# apollo510 register map
Vendor: Ambiq Micro; Series: Apollo; File version: 1.0
CPU: CM55 r1p1, little endian, MPU, FPU, double-precision FPU, DSP, I-cache, D-cache, VTOR, ITCM, DTCM, 4 interrupt priority bits, 0 interrupts, 8 SAU regions
Registers are 32-bit, read-write, reset 0x0 unless marked. A register's access mark holds for its fields unless they carry their own. Offsets are from the block's base; [hi:lo] are bit positions; 'fields as' and 'values as' point back to an identical list.

## PDM0 — PDM Audio
Base 0x40201000
Same registers: PDM1 0x40202000, PDM2 0x40203000, PDM3 0x40204000
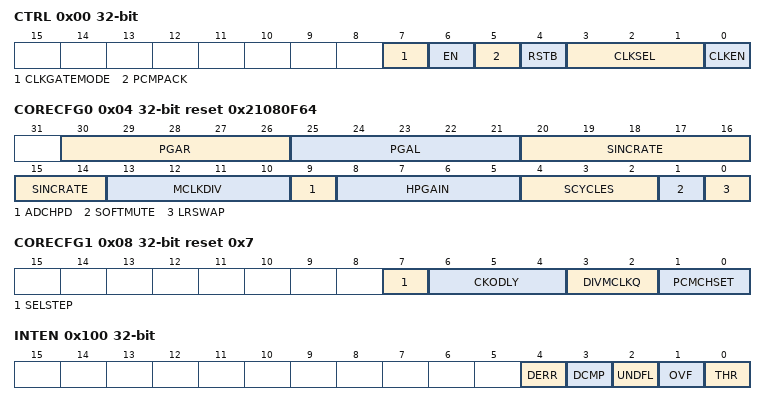
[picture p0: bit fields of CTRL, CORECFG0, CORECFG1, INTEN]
0x00 CTRL — PDM Control
  [7] CLKGATEMODE — Clock gating mode. 0 = clock always enabled when DMA is enabled. 1 = clock is enabled when there is actual DMA transfer
  [6] EN — PDM enable register
    0=DIS (Disable PDM.); 1=EN (Enable PDM.)
  [5] PCMPACK — Enable PCM packing. Only 24-bit unpacked mode supported.
    0=DIS (Disable PCM packing.); 1=EN (Enable PCM packing.)
  [4] RSTB — Reset IP core. 0 puts the core in reset; 1 takes the core out of reset.
    0=RESET (Put the core in reset.); 1=NORMAL (Core not in reset.)
  [3:1] CLKSEL — PDM Master Clock select (24.576MHz).
    0=HFRC2_31MHz (31MHz sourced from the HFRC2); 1=XTAL_HS (High Frequency XTAL); 2=HFRC_24MHz (24MHz sourced from the HFRC); 3=XTAL_HS_DIV2 (High Frequency XTAL Divide by 2); 4=XTAL_HS_DIV4 (High Frequency XTAL Divide by 4); 5=EXTREFCLK (External reference clock); 6=OFF (Static 0)
  [0] CLKEN — PDM Clock enable. If multiple clocks are enabled, priority is HFRC2, HF XTAL, HFRC.
    0=DIS (Disable serial clock); 1=EN (Enable serial clock)
0x04 CORECFG0 reset 0x21080F64 — PDM to PCM Core Configuration
  [30:26] PGAR — Right Channel PGA Gain: +1.5dB/step, -12dB ~ +34.5dB;
    0=M12_0DB (Right channel PGA gain = -12.0 dB); 1=M10_5DB (Right channel PGA gain = -10.5 dB); 2=M9_0DB (Right channel PGA gain = -9.0 dB); 3=M7_5DB (Right channel PGA gain = -7.5 dB); 4=M6_0DB (Right channel PGA gain = -6.0 dB); 5=M4_5DB (Right channel PGA gain = -4.5 dB); 6=M3_0DB (Right channel PGA gain = -3.0 dB); 7=M1_5DB (Right channel PGA gain = -1.5 dB); 8=0DB (Right channel PGA gain = 0 DB); 9=P1_5DB (Right channel PGA gain = 1.5 dB); 10=P3_0DB (Right channel PGA gain = 3.0 dB); 11=P4_5DB (Right channel PGA gain = 4.5 dB); 12=P6_0DB (Right channel PGA gain = 6.0 DB); 13=P7_5DB (Right channel PGA gain = 7.5 dB); 14=P9_0DB (Right channel PGA gain = 9.0 dB); 15=P10_5DB (Right channel PGA gain = 10.5 dB); 16=P12_0DB (Right channel PGA gain = 12.0 DB); 17=P13_5DB (Right channel PGA gain = 13.5 dB); 18=P15_0DB (Right channel PGA gain = 15.0 dB); 19=P16_5DB (Right channel PGA gain = 16.5 dB); 20=P18_0DB (Right channel PGA gain = 18.0 DB); 21=P19_5DB (Right channel PGA gain = 19.5 dB); 22=P21_0DB (Right channel PGA gain = 21.0 dB); 23=P22_5DB (Right channel PGA gain = 22.5 dB); 24=P24_0DB (Right channel PGA gain = 24.0 DB); 25=P25_5DB (Right channel PGA gain = 25.5 dB); 26=P27_0DB (Right channel PGA gain = 27.0 dB); 27=P28_5DB (Right channel PGA gain = 28.5 dB); 28=P30_0DB (Right channel PGA gain = 30.0 DB); 29=P31_5DB (Right channel PGA gain = 31.5 dB); 30=P33_0DB (Right channel PGA gain = 33.0 dB); 31=P34_5DB (Right channel PGA gain = 34.5 dB)
  [25:21] PGAL — Left Channel PGA Gain: +1.5dB/step, -12dB ~ +34.5dB; enum name = M12_0DB value = 0x0 desc = Left channel PGA gain = -12.0 dB
    1=M10_5DB (Left channel PGA gain = -10.5 dB); 2=M9_0DB (Left channel PGA gain = -9.0 dB); 3=M7_5DB (Left channel PGA gain = -7.5 dB); 4=M6_0DB (Left channel PGA gain = -6.0 dB); 5=M4_5DB (Left channel PGA gain = -4.5 dB); 6=M3_0DB (Left channel PGA gain = -3.0 dB); 7=M1_5DB (Left channel PGA gain = -1.5 dB); 8=0DB (Left channel PGA gain = 0 DB); 9=P1_5DB (Left channel PGA gain = 1.5 dB); 10=P3_0DB (Left channel PGA gain = 3.0 dB); 11=P4_5DB (Left channel PGA gain = 4.5 dB); 12=P6_0DB (Left channel PGA gain = 6.0 DB); 13=P7_5DB (Left channel PGA gain = 7.5 dB); 14=P9_0DB (Left channel PGA gain = 9.0 dB); 15=P10_5DB (Left channel PGA gain = 10.5 dB); 16=P12_0DB (Left channel PGA gain = 12.0 DB); 17=P13_5DB (Left channel PGA gain = 13.5 dB); 18=P15_0DB (Left channel PGA gain = 15.0 dB); 19=P16_5DB (Left channel PGA gain = 16.5 dB); 20=P18_0DB (Left channel PGA gain = 18.0 DB); 21=P19_5DB (Left channel PGA gain = 19.5 dB); 22=P21_0DB (Left channel PGA gain = 21.0 dB); 23=P22_5DB (Left channel PGA gain = 22.5 dB); 24=P24_0DB (Left channel PGA gain = 24.0 DB); 25=P25_5DB (Left channel PGA gain = 25.5 dB); 26=P27_0DB (Left channel PGA gain = 27.0 dB); 27=P28_5DB (Left channel PGA gain = 28.5 dB); 28=P30_0DB (Left channel PGA gain = 30.0 DB); 29=P31_5DB (Left channel PGA gain = 31.5 dB); 30=P33_0DB (Left channel PGA gain = 33.0 dB); 31=P34_5DB (Left channel PGA gain = 34.5 dB)
  [20:14] SINCRATE — Sinc decimation rate. SINC_RATE = OSR /2. OSR = Fsin / Fsout. Must be even. 16 to 64 allowed. 96 allowed for special configuration.
  [13:10] MCLKDIV — PDMA_CKO frequency divisor. MCLKDIV > 0. MCLKDIV = 0 PROHIBITED. MCLKDIV = (PDM_CLK /Fsin / (DIVMCLKQ + 1)) -1
  [9] ADCHPD — Disable high pass filter when = 1
    0=DIS (Disable high pass filter.); 1=EN (Enable high pass filter.)
  [8:5] HPGAIN — Adjust High Pass filter coefficients
  [4:2] SCYCLES — Set number of PDMA_CKO cycles during gain setting changes or soft mute
    0=0CYCLES (Zero PDMA_CK0 clock cycles during gain setting changes or soft mute.); 1=1CYCLES (One PDMA_CK0 clock cycle during gain setting changes or soft mute.); 2=2CYCLES (Two PDMA_CK0 clock cycles during gain setting changes or soft mute.); 3=3CYCLES (Three PDMA_CK0 clock cycles during gain setting changes or soft mute.); 4=4CYCLES (Four PDMA_CK0 clock cycles during gain setting changes or soft mute.); 5=5CYCLES (Five PDMA_CK0 clock cycles during gain setting changes or soft mute.); 6=6CYCLES (Six PDMA_CK0 clock cycles during gain setting changes or soft mute.); 7=7CYCLES (Seven PDMA_CK0 clock cycles during gain setting changes or soft mute.)
  [1] SOFTMUTE — Soft mute enable when = 1
  [0] LRSWAP — Left/Right channel swap when = 1
    0=DIS (Disable left/right channel swapping.); 1=EN (Enable left/right channel swapping.)
0x08 CORECFG1 reset 0x7 — PDM to PCM Extra Configuration
  [7] SELSTEP — Fine grain step size for smooth PGA or Softmute attenuation transition 0: 0.13dB 1: 0.26dB
    0=0_13DB (0.13dB fine grain step size.); 1=0_26DB (0.26dB fine grain step size.)
  [6:4] CKODLY — PDMA_CKO clock phase delay in terms of PDMCLK period to internal sampler
    0=0CYCLES (No extra PDMCLK cycle delays.); 1=1CYCLES (One xtra PDMCLK cycle delay.); 2=2CYCLES (Two extra PDMCLK cycle delays.); 3=3CYCLES (Three extra PDMCLK cycle delays.); 4=4CYCLES (Four extra PDMCLK cycle delays.); 5=5CYCLES (Five extra PDMCLK cycle delays.); 6=6CYCLES (Six extra PDMCLK cycle delays.); 7=7CYCLES (Seven extra PDMCLK cycle delays.)
  [3:2] DIVMCLKQ — Divide down ratio for generating internal master MCLKQ. DIVMCLKQ > 0. DIVMCLKQ = 0 PROHIBITED. Recommend value of 1. Fmclkq = Fpdmclk/(DIVMCLKQ+1).
  [1:0] PCMCHSET — PCM output chanel 0xsetting
    0=CHANDIS (Channel Disabled); 1=MONOL (MONO Left); 2=MONOR (MONO right); 3=STEREO
0x0C CORECTRL reset 0x80000434 — PDM to PCM Control
  [31:0] CORECTRL — Overall control of PDM core. Internal use only
0x10 FIFOCNT — FIFO count
  [5:0] FIFOCNT — Valid 32-bit entries currently in the FIFO.
0x14 FIFOREAD
  [31:0] FIFOREAD — FIFO read data.
0x18 FIFOFLUSH
  [0] FIFOFLUSH
0x1C FIFOTHR reset 0x10 — FIFO Threshold
  [4:0] FIFOTHR — FIFO Threshold value. When the FIFO count is equal to, or larger than this value (in words), a THR interrupt is generated (if enabled). If used for DMA purposes then only supported values are 0x4, 0x8, 0xc, 0x10, 0x14, 0x18 and 0x1C.
0x100 INTEN — Set bits in this register to allow this module to generate the corresponding interrupt.
  [4] DERR — DMA Error receieved
  [3] DCMP — DMA completed a transfer
  [2] UNDFL — This is the FIFO underflow interrupt.
  [1] OVF — This is the FIFO overflow interrupt.
  [0] THR — This is the FIFO threshold interrupt.
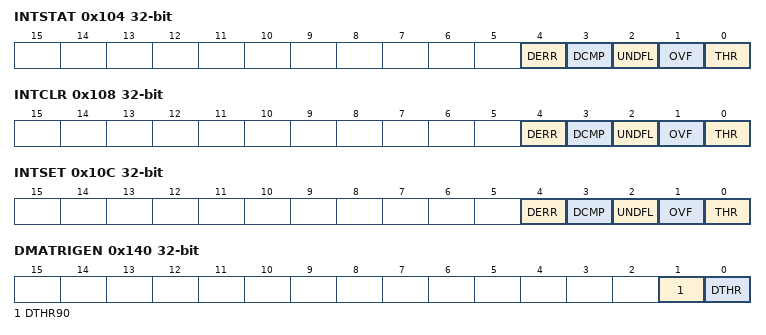
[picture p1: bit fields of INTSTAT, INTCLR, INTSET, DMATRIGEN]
0x104 INTSTAT — Read bits from this register to discover the cause of a recent interrupt.
  fields as INTEN
0x108 INTCLR — Write a 1 to a bit in this register to clear the interrupt status associated with that bit.
  fields as INTEN
0x10C INTSET — Write a 1 to a bit in this register to instantly generate an interrupt from this module. (Generally used for testing purposes).
  fields as INTEN
0x140 DMATRIGEN — DMA Trigger Enable
  [1] DTHR90 — Trigger DMA at FIFO 90 percent full. This signal is also used internally for AUTOHIP function
  [0] DTHR — Trigger DMA upon when FIFO iss filled to level indicated by the FIFO THRESHOLD,at granularity of 16 bytes only
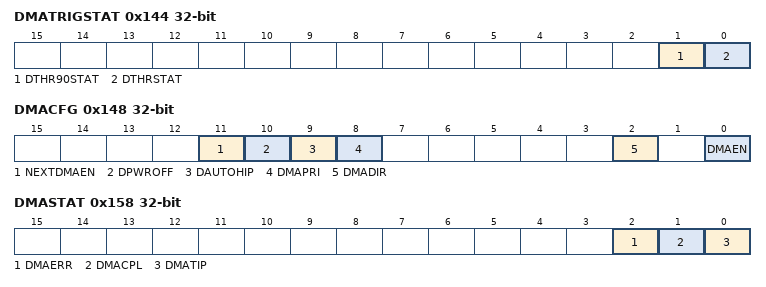
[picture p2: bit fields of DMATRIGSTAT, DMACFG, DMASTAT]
0x144 DMATRIGSTAT — DMA Trigger Status
  [1] DTHR90STAT — Triggered DMA from FIFO reaching 90 percent full
  [0] DTHRSTAT — Triggered DMA from FIFO reaching threshold
0x148 DMACFG — DMA Configuration
  [11] NEXTDMAEN — Next DMA Request Feature Enable. When set, SW shall not program TOTCOUNT and TARGADDR. Instead, SW shall program TOTCOUNTNEXT and TARGADDRNEXT, and load them into HW DMA request pipeline using DMAENNEXT bit.
  [10] DPWROFF — Power Off the ADC System upon DMACPL.
  [9] DAUTOHIP — Raise priority to high on fifo full, and DMAPRI set to low
  [8] DMAPRI — Sets the Priority of the DMA request
    0=LOW (Low Priority (service as best effort)); 1=HIGH (High Priority (service immediately))
  [2] DMADIR — Direction
    0=P2M (Peripheral to Memory (SRAM) transaction. THe PDM module will only DMA to memory.); 1=M2P (Memory to Peripheral transaction. Not available for PDM module)
  [0] DMAEN — DMA Enable
    0=DIS (Disable DMA Function); 1=EN (Enable DMA Function)
0x154 DMATARGADDR — DMA Target Address
  [31:0] LTARGADDR — DMA Target Address. This register is not updated with the current address of the DMA, but will remain static with the original address during the DMA transfer.
0x158 DMASTAT — DMA Status
  [2] DMAERR — DMA Error
  [1] DMACPL — DMA Transfer Complete
  [0] DMATIP — DMA Transfer In Progress
0x160 DMATARGADDRNEXT — DMA Target Address
  [31:0] TARGADDRNEXT — Next DMA Target Address. This register is not updated with the current address of the DMA, but will remain static with the original address during the DMA transfer.
0x164 DMATOTCOUNTNEXT — Next DMA Total Count
  [19:0] TOTCOUNTNEXT — Next Total Transfer Count.
0x168 DMAENNEXTCTRL — Enable Next DMA Job
  [0] DMAENNEXT — SW set this bit after setting up TOTCOUNTNEXT and TARGADDRNEXT register fields. HW will then auto-load TOTCOUNTNEXT and TARGADDRNEXT values when its current DMA job completes, and auto-clear this DMAENNEXT bit. SW can then reload a new DMA job with new TOTCOUNTNEXT and TARGADDRNEXT values.
0x250 DMATOTCOUNT — DMA Total Transfer Count
  [19:0] TOTCOUNT — Total Transfer Count. The transfer count must be a multiple of the THR setting to avoid DMA overruns.
